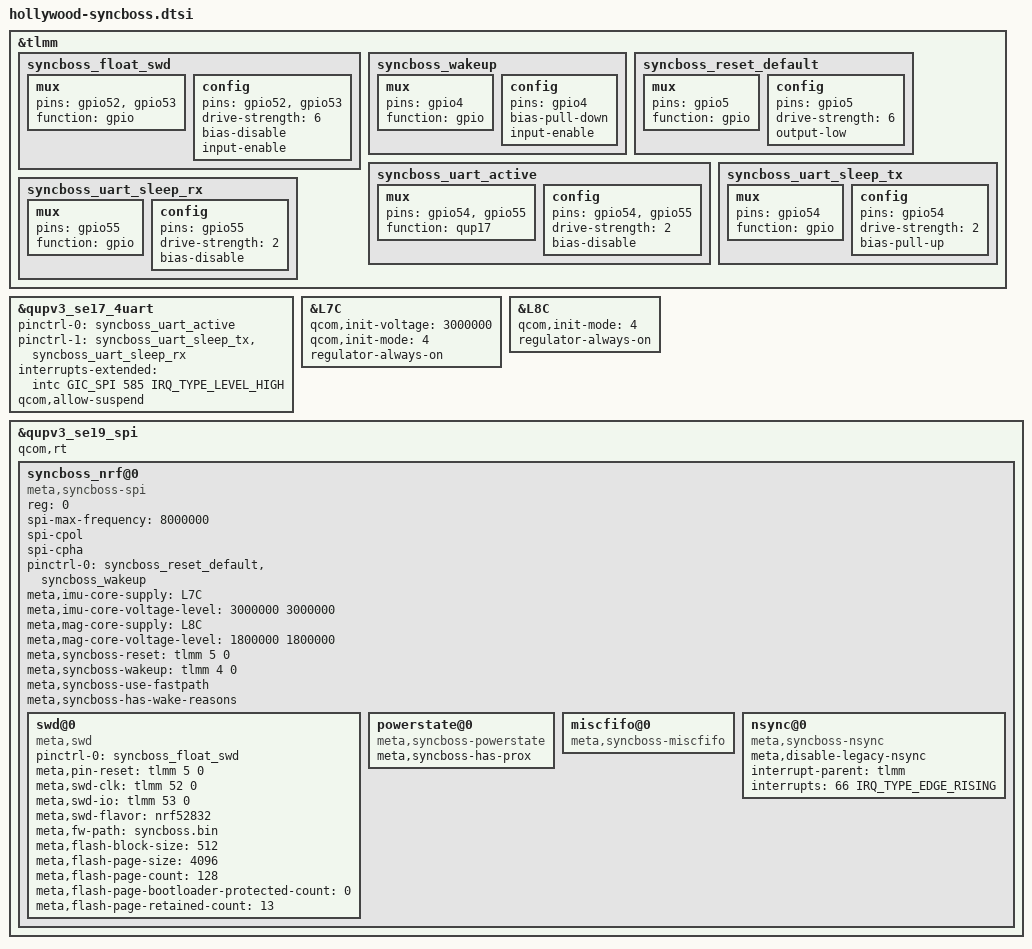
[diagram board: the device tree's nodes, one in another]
&tlmm {
	syncboss_float_swd: syncboss_float_swd {
		mux {
			pins = "gpio52", "gpio53";
			function = "gpio";
		};

		config {
			pins = "gpio52", "gpio53";
			drive-strength = <6>;
			bias-disable;
			input-enable;
		};
	};

	syncboss_wakeup: syncboss_wakeup {
		mux {
			pins = "gpio4";
			function = "gpio";
		};

		config {
			pins = "gpio4";
			bias-pull-down;
			input-enable;
		};
	};

	syncboss_reset_default: syncboss_reset_default {
		mux {
			pins = "gpio5";
			function = "gpio";
		};

		config {
			pins = "gpio5";
			drive-strength = <6>;
			output-low;
		};
	};

	syncboss_uart_active: syncboss_uart_active {
		mux {
			pins = "gpio54", "gpio55";
			function = "qup17";
		};

		config {
			pins = "gpio54", "gpio55";
			drive-strength = <2>;
			bias-disable;
		};
	};

	syncboss_uart_sleep_tx: syncboss_uart_sleep_tx {
		mux {
			pins = "gpio54";
			function = "gpio";
		};

		config {
			pins = "gpio54";
			drive-strength = <2>;
			bias-pull-up;
		};
	};

	syncboss_uart_sleep_rx: syncboss_uart_sleep_rx {
		mux {
			pins = "gpio55";
			function = "gpio";
		};

		config {
			pins = "gpio55";
			drive-strength = <2>;
			bias-disable;
		};
	};
};

&qupv3_se17_4uart {
	status = "ok";

	pinctrl-0 = <&syncboss_uart_active>;
	pinctrl-1 = <&syncboss_uart_sleep_tx &syncboss_uart_sleep_rx>;
	interrupts-extended = <&intc GIC_SPI 585 IRQ_TYPE_LEVEL_HIGH>;
	qcom,allow-suspend;
};

&L7C {
	qcom,init-voltage = <3000000>;
	qcom,init-mode = <4>; /* RPMH_REGULATOR_MODE_HPM */
	regulator-always-on;
};

&L8C {
	qcom,init-mode = <4>; /* RPMH_REGULATOR_MODE_HPM */
	regulator-always-on;
};

&qupv3_se19_spi {
	status = "ok";
	qcom,rt;

	syncboss_nrf@0 {
		status = "okay";
		compatible = "meta,syncboss-spi";
		reg = <0>;
		spi-max-frequency = <8000000>;

		spi-cpol;
		spi-cpha;

		pinctrl-names = "default";
		pinctrl-0 = <&syncboss_reset_default &syncboss_wakeup>;

		meta,imu-core-supply = <&L7C>;
		meta,imu-core-voltage-level = <3000000 3000000>;
		meta,mag-core-supply = <&L8C>;
		meta,mag-core-voltage-level = <1800000 1800000>;

		meta,syncboss-reset  = <&tlmm 5 0>;
		meta,syncboss-wakeup  = <&tlmm 4 0>;

		meta,syncboss-use-fastpath;
		meta,syncboss-has-wake-reasons;

		swd@0 {
			compatible = "meta,swd";

			pinctrl-names = "default";
			pinctrl-0 = <&syncboss_float_swd>;

			meta,pin-reset = <&tlmm 5 0>;
			meta,swd-clk = <&tlmm 52 0>;
			meta,swd-io = <&tlmm 53 0>;

			meta,swd-flavor = "nrf52832";
			meta,fw-path = "syncboss.bin";
			meta,flash-block-size = <512>;
			meta,flash-page-size = <4096>;
			meta,flash-page-count = <128>;
			meta,flash-page-bootloader-protected-count = <0>;
			meta,flash-page-retained-count = <13>;
		};

		powerstate@0 {
			compatible = "meta,syncboss-powerstate", "meta,syncboss-consumer";
			meta,syncboss-has-prox;
		};

		miscfifo@0 {
			compatible = "meta,syncboss-miscfifo", "meta,syncboss-consumer";
		};

		nsync@0 {
			compatible = "meta,syncboss-nsync", "meta,syncboss-consumer";

			meta,disable-legacy-nsync;

			interrupt-parent = <&tlmm>;
			interrupts = <66 IRQ_TYPE_EDGE_RISING>;
			interrupt-names = "nsync";
		};
	};
};
